# R7FA8D1BH register map
Vendor: Renesas; Series: RA8; File version: 1.2
CPU: CM85 r0p0, little endian, MPU, FPU, VTOR, 4 interrupt priority bits
Registers are 32-bit, read-write, reset 0x0 unless marked. A register's access mark holds for its fields unless they carry their own. Offsets are from the block's base; [hi:lo] are bit positions; {n}, {i} and the like mark numbered series; 'fields as' and 'values as' point back to an identical list.

## DMAC0 — Direct memory access controller 0
Base 0x4000A000
Same registers: DMAC1 0x4000A040, DMAC2 0x4000A080, DMAC3 0x4000A0C0, DMAC4 0x4000A100, DMAC5 0x4000A140, DMAC6 0x4000A180, DMAC7 0x4000A1C0, DMAC{n}_NS {0x5000A000+0x40*n} (n=0..7)
0x00 DMSAR — DMA Source Address Register
  [31:0] DMSAR — Specifies the transfer source start address.
0x04 DMDAR — DMA Destination Address Register
  [31:0] DMDAR — Specifies the transfer destination start address.
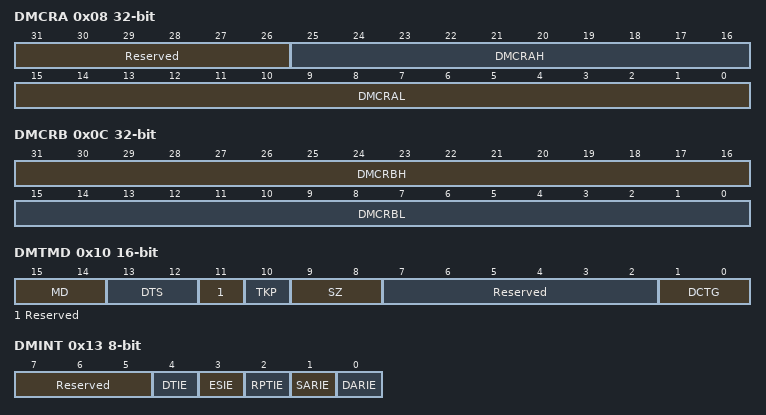
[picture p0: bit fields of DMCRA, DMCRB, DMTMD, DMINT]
0x08 DMCRA — DMA Transfer Count Register
  [31:26] Reserved — These bits are read as 000000. The write value should be 000000.
  [25:16] DMCRAH — Upper bits of transfer count
  [15:0] DMCRAL — Lower bits of transfer count
0x0C DMCRB — DMA Block Transfer Count Register
  [31:16] DMCRBH — Specifies the number of block transfer operations or repeat transfer operations.
  [15:0] DMCRBL — Functions as a number of block transfer counter or repeat transfer counter.
0x10 DMTMD 16-bit — DMA Transfer Mode Register
  [15:14] MD — Transfer Mode Select
    0=Normal transfer; 1=Repeat transfer; 2=Block transfer; 3=Repeat-block transfer
  [13:12] DTS — Repeat Area Select
    0=Specify destination as the repeat area or block area; 1=Specify source as the repeat area or block area; 2=Do not specify repeat area or block area; 3=Setting prohibited
  [11] Reserved — This bit is read as 0. The write value should be 0.
  [10] TKP — Transfer Keeping
    0=Transfer is stopped by completion of specified total number of transfer operations; 1=Transfer is not stopped by completion of specified total number of transfer operations. (free-running)
  [9:8] SZ — Transfer Data Size Select
    0=8 bits; 1=16 bits; 2=32 bits; 3=Setting prohibited
  [7:2] Reserved — These bits are read as 000000. The write value should be 000000.
  [1:0] DCTG — Transfer Request Source Select
    0=Software; 1=Interrupts from peripheral modules or external interrupt input pins; other=others (Setting prohibited)
0x13 DMINT 8-bit — DMA Interrupt Setting Register
  [7:5] Reserved — These bits are read as 000. The write value should be 000.
  [4] DTIE — Transfer End Interrupt Enable
    0=Disable; 1=Enable
  [3] ESIE — Transfer Escape End Interrupt Enable
    0=Disable; 1=Enable
  [2] RPTIE — Repeat Size End Interrupt Enable
    0=Disable; 1=Enable
  [1] SARIE — Source Address Extended Repeat Area Overflow Interrupt Enable
    0=Disable; 1=Enable
  [0] DARIE — Destination Address Extended Repeat Area Overflow Interrupt Enable
    0=Disable; 1=Enable
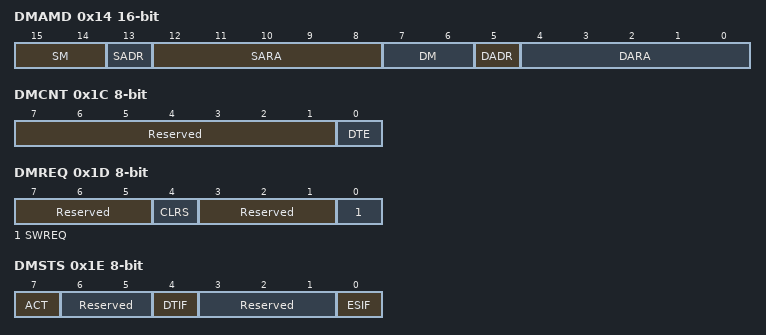
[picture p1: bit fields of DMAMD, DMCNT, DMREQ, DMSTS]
0x14 DMAMD 16-bit — DMA Address Mode Register
  [15:14] SM — Source Address Update Mode
    0=Fixed address; 1=Offset addition; 2=Incremented address; 3=Decremented address
  [13] SADR — Source Address Update Select After Reload
    0=Only reloading; 1=Add index after reloading
  [12:8] SARA — Source Address Extended Repeat Area Specifies the extended repeat area on the source address. For details on the settings.
  [7:6] DM — Destination Address Update Mode
    values as SM
  [5] DADR — Destination Address Update Select After Reload
    0=Only reloading; 1=Add index after reloading
  [4:0] DARA — Destination Address Extended Repeat Area Specifies the extended repeat area on the destination address. For details on the settings.
0x18 DMOFR — DMA Offset Register
  [31:0] DMOFR — Specifies the offset when offset addition is selected as the address update mode for transfer source or destination.
0x1C DMCNT 8-bit — DMA Transfer Enable Register
  [7:1] Reserved — These bits are read as 0000000. The write value should be 0000000.
  [0] DTE read-modifies — DMA Transfer Enable
    0=Disable; 1=Enable
0x1D DMREQ 8-bit — DMA Software Start Register
  [7:5] Reserved — These bits are read as 000. The write value should be 000.
  [4] CLRS — DMA Software Start Bit Auto Clear Select
    0=Clear SWREQ bit after DMA transfer is started by software; 1=Do not clear SWREQ bit after DMA transfer is started by software
  [3:1] Reserved — These bits are read as 000. The write value should be 000.
  [0] SWREQ read-modifies — DMA Software Start
    0=Do not request DMA transfer; 1=Request DMA transfer
0x1E DMSTS 8-bit — DMAC Module Activation Register
  [7] ACT ro — DMA Active Flag
    0=DMAC operation is suspended; 1=DMAC is operating
  [6:5] Reserved — These bits are read as 00. The write value should be 00.
  [4] DTIF write-0-clears read-modifies — Transfer End Interrupt Flag
    0=No interrupt occurred; 1=Interrupt occurred
  [3:1] Reserved — These bits are read as 000. The write value should be 000.
  [0] ESIF write-0-clears read-modifies — Transfer Escape End Interrupt Flag
    0=A transfer escape end interrupt has not been generated; 1=A transfer escape end interrupt has been generated
0x20 DMSRR — DMA Source Reload Address Register
  [31:0] DMSRR — Specifies the transfer source reload address.
0x24 DMDRR — DMA Destination Reload Address Register
  [31:0] DMDRR — Specifies the transfer destination reload address.
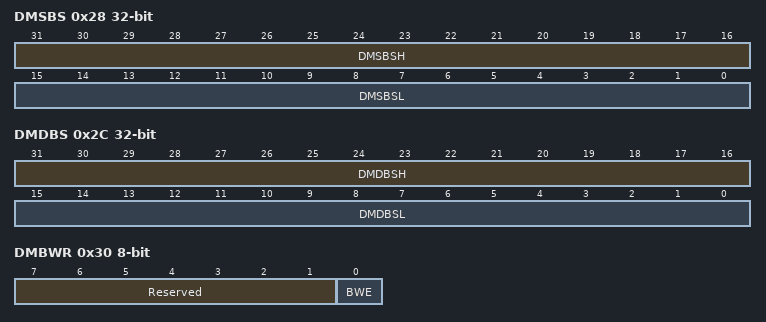
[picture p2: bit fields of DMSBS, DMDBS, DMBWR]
0x28 DMSBS — DMA Source Buffer Size Register
  [31:16] DMSBSH — Specifies the repeat-area size in repeat block transfer mode.
  [15:0] DMSBSL — Functions as data transfer counter in repeat block transfer mode.
0x2C DMDBS — DMA Source Buffer Size Register
  [31:16] DMDBSH — Specifies the repeat-area size in repeat block transfer mode.
  [15:0] DMDBSL — Functions as data transfer counter in repeat block transfer mode.
0x30 DMBWR 8-bit — DMA Bufferable Write Enable Register
  [7:1] Reserved — These bits are read as 0000000. The write value should be 0000000.
  [0] BWE — Bufferable Write Enable
    0=Disables Bufferable Write; 1=Enables Bufferable Write
